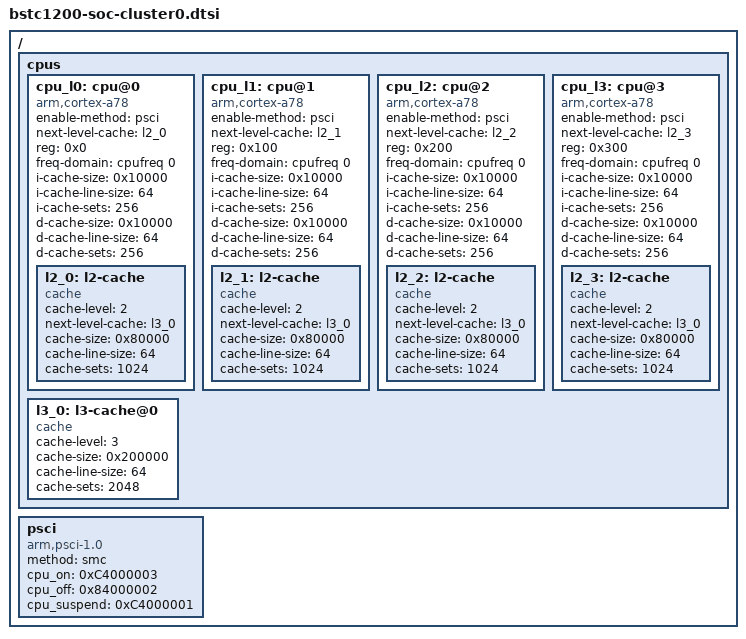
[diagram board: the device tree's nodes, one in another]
// SPDX-License-Identifier: GPL-2.0+

/****************************************************************************************/
/*	c0_lockstep/c1_split	1 + 5: c0 0x0 + c0 0x100 \ c1 0x0 ~ 0x300
 *	c0_lockstep/c1_lockstep	1 + 3: c0 0x0 + c0 0x100 \ c1 0x0 ~ 0x100
 *	split			2 + 6: c0 0x0 ~ 0x100 + c0 0x200 ~ 0x300 \ c1 0x0 ~ 0x300
 *	split			4 + 4: c0 0x0 ~ 0x300 + c1 0x0 ~ 0x300
 */
/****************************************************************************************/
/ { 
	cpus {
		#address-cells = <1>;
		#size-cells = <0>;

		cpu_l0: cpu@0 {
			compatible = "arm,cortex-a78", "arm,armv8";
			device_type = "cpu";
			enable-method = "psci";
			next-level-cache = <&l2_0>;
			reg = <0x0>;
			freq-domain = <&cpufreq 0>;

			i-cache-size = <0x10000>;
			i-cache-line-size = <64>;
			i-cache-sets = <256>;
			d-cache-size = <0x10000>;
			d-cache-line-size = <64>;
			d-cache-sets = <256>;

			l2_0: l2-cache {
				compatible = "cache";
				cache-level = <2>;
				next-level-cache = <&l3_0>;
				cache-size = <0x80000>;
				cache-line-size = <64>;
				cache-sets = <1024>;
			};
		};

		cpu_l1: cpu@1 {
			compatible = "arm,cortex-a78", "arm,armv8";
			device_type = "cpu";
			enable-method = "psci";
			next-level-cache = <&l2_1>;
			reg = <0x100>;
			freq-domain = <&cpufreq 0>;

			i-cache-size = <0x10000>;
			i-cache-line-size = <64>;
			i-cache-sets = <256>;
			d-cache-size = <0x10000>;
			d-cache-line-size = <64>;
			d-cache-sets = <256>;

			l2_1: l2-cache {
				compatible = "cache";
				cache-level = <2>;
				next-level-cache = <&l3_0>;
				cache-size = <0x80000>;
				cache-line-size = <64>;
				cache-sets = <1024>;
			};
		};

		cpu_l2: cpu@2 {
			compatible = "arm,cortex-a78", "arm,armv8";
			device_type = "cpu";
			enable-method = "psci";
			next-level-cache = <&l2_2>;
			reg = <0x200>;
			freq-domain = <&cpufreq 0>;

			i-cache-size = <0x10000>;
			i-cache-line-size = <64>;
			i-cache-sets = <256>;
			d-cache-size = <0x10000>;
			d-cache-line-size = <64>;
			d-cache-sets = <256>;

			l2_2: l2-cache {
				compatible = "cache";
				cache-level = <2>;
				next-level-cache = <&l3_0>;
				cache-size = <0x80000>;
				cache-line-size = <64>;
				cache-sets = <1024>;
			};
		};

		cpu_l3: cpu@3 {
			compatible = "arm,cortex-a78", "arm,armv8";
			device_type = "cpu";
			enable-method = "psci";
			next-level-cache = <&l2_3>;
			reg = <0x300>;
			freq-domain = <&cpufreq 0>;

			i-cache-size = <0x10000>;
			i-cache-line-size = <64>;
			i-cache-sets = <256>;
			d-cache-size = <0x10000>;
			d-cache-line-size = <64>;
			d-cache-sets = <256>;

			l2_3: l2-cache {
				compatible = "cache";
				cache-level = <2>;
				next-level-cache = <&l3_0>;
				cache-size = <0x80000>;
				cache-line-size = <64>;
				cache-sets = <1024>;
			};
		};

		l3_0: l3-cache@0 {
			compatible = "cache";
			cache-level = <3>;
			cache-size = <0x200000>;
			cache-line-size = <64>;
			cache-sets = <2048>;
		};
	};

	psci {
		compatible	= "arm,psci-1.0";
		method		= "smc";
		cpu_on		= <0xC4000003>;
		cpu_off		= <0x84000002>;
		cpu_suspend	= <0xC4000001>;
	};
};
